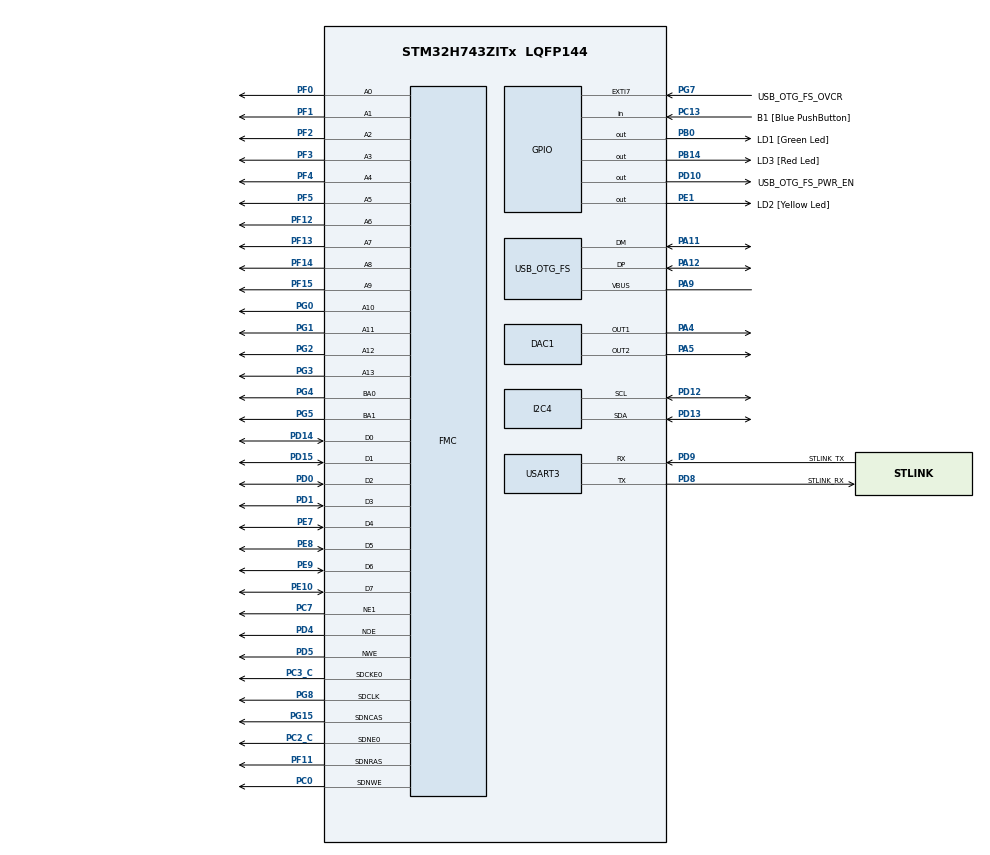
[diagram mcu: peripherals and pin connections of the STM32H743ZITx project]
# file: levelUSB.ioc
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CORTEX_M7.AccessPermission-Cortex_Memory_Protection_Unit_Region0_Settings=MPU_REGION_NO_ACCESS
CORTEX_M7.AccessPermission-Cortex_Memory_Protection_Unit_Region1_Settings=MPU_REGION_FULL_ACCESS
CORTEX_M7.BaseAddress-Cortex_Memory_Protection_Unit_Region0_Settings=0x00
CORTEX_M7.BaseAddress-Cortex_Memory_Protection_Unit_Region1_Settings=0x70000000
CORTEX_M7.CPU_DCache=Enabled
CORTEX_M7.CPU_ICache=Enabled
CORTEX_M7.DisableExec-Cortex_Memory_Protection_Unit_Region0_Settings=MPU_INSTRUCTION_ACCESS_DISABLE
CORTEX_M7.Enable-Cortex_Memory_Protection_Unit_Region0_Settings=MPU_REGION_ENABLE
CORTEX_M7.Enable-Cortex_Memory_Protection_Unit_Region1_Settings=MPU_REGION_ENABLE
CORTEX_M7.IsCacheable-Cortex_Memory_Protection_Unit_Region0_Settings=MPU_ACCESS_NOT_CACHEABLE
CORTEX_M7.IsCacheable-Cortex_Memory_Protection_Unit_Region1_Settings=MPU_ACCESS_CACHEABLE
CORTEX_M7.IsShareable-Cortex_Memory_Protection_Unit_Region0_Settings=MPU_ACCESS_SHAREABLE
CORTEX_M7.MPU_Control=MPU_PRIVILEGED_DEFAULT
CORTEX_M7.Size-Cortex_Memory_Protection_Unit_Region0_Settings=MPU_REGION_SIZE_4GB
CORTEX_M7.Size-Cortex_Memory_Protection_Unit_Region1_Settings=MPU_REGION_SIZE_256MB
CORTEX_M7.SubRegionDisable-Cortex_Memory_Protection_Unit_Region0_Settings=0x87
DAC1.DAC_Channel-DAC_OUT1=DAC_CHANNEL_1
DAC1.DAC_Channel-DAC_OUT2=DAC_CHANNEL_2
FATFS._FS_EXFAT=1
FATFS._FS_RPATH=1
FATFS._MAX_SS=512
FATFS._USE_LFN=3
FATFS._USE_MUTEX=1
FMC.CASLatency1=FMC_SDRAM_CAS_LATENCY_2
FMC.ExitSelfRefreshDelay1=9
FMC.RCDDelay1=2
FMC.RPDelay1=2
FMC.RPDelay2=2
FMC.ReadBurst1=FMC_SDRAM_RBURST_ENABLE
FMC.ReadBurst2=FMC_SDRAM_RBURST_ENABLE
FMC.RowCycleDelay1=8
FMC.RowCycleDelay2=8
FMC.SelfRefreshTime1=4
FMC.WriteOperation1=FMC_WRITE_OPERATION_ENABLE
FMC.WriteRecoveryTime1=4
FREERTOS.Tasks01=startupTask,24,1024,StartDefaultTask,Default,NULL,Dynamic,NULL,NULL
FREERTOS.configMINIMAL_STACK_SIZE=128
FREERTOS.configTOTAL_HEAP_SIZE=35360
FREERTOS.configUSE_NEWLIB_REENTRANT=0
FREERTOS.copyHeapFile=1
I2C4.Timing=0x109093DC
Mcu.Family=STM32H7
Mcu.Name=STM32H743ZITx
Mcu.Package=LQFP144
Mcu.UserConstants=SDRAM_MODEREG_BURST_LENGTH_1,(0x00);SDRAM_MODEREG_BURST_TYPE_SEQUENTIAL,(0x00 << 3);SDRAM_MODEREG_CAS_LATENCY_2,(0x2 << 4);SDRAM_MODEREG_CAS_LATENCY_3,(0x3 << 4);SDRAM_MODEREG_WRITE_BURST_NORMAL,(0x0 << 9);SDRAM_MODEREG_OCD_NORMAL,(0x0 << 10);SDRAM_TIMEOUT,1
Mdma.MDMA_Channel0.Request0=SW
Mdma.MDMA_Channel0.RequestsNb=1
Mdma.MDMA_Channel0.SW.0.BlockCount=0
Mdma.MDMA_Channel0.SW.0.BlockDataLength=0
Mdma.MDMA_Channel0.SW.0.BufferTransferLength=1
Mdma.MDMA_Channel0.SW.0.CircularMode=MDMA_LINEAR_LIST
Mdma.MDMA_Channel0.SW.0.DataAlignment=MDMA_DATAALIGN_PACKENABLE
Mdma.MDMA_Channel0.SW.0.DestBlockAddressOffset=0
Mdma.MDMA_Channel0.SW.0.DestBurst=MDMA_DEST_BURST_SINGLE
Mdma.MDMA_Channel0.SW.0.DestDataSize=MDMA_DEST_DATASIZE_BYTE
Mdma.MDMA_Channel0.SW.0.DestinationInc=MDMA_DEST_INC_BYTE
Mdma.MDMA_Channel0.SW.0.DstAddress=0
Mdma.MDMA_Channel0.SW.0.Endianness=MDMA_LITTLE_ENDIANNESS_PRESERVE
Mdma.MDMA_Channel0.SW.0.Instance=MDMA_Channel0
Mdma.MDMA_Channel0.SW.0.MaskAddress=0
Mdma.MDMA_Channel0.SW.0.MaskData=0
Mdma.MDMA_Channel0.SW.0.Priority=MDMA_PRIORITY_LOW
Mdma.MDMA_Channel0.SW.0.Rank=First
Mdma.MDMA_Channel0.SW.0.SourceBlockAddressOffset=0
Mdma.MDMA_Channel0.SW.0.SourceBurst=MDMA_SOURCE_BURST_SINGLE
Mdma.MDMA_Channel0.SW.0.SourceDataSize=MDMA_SRC_DATASIZE_BYTE
Mdma.MDMA_Channel0.SW.0.SourceInc=MDMA_SRC_INC_BYTE
Mdma.MDMA_Channel0.SW.0.SrcAddress=0
Mdma.MDMA_Channel0.SW.0.TransferTriggerMode=MDMA_BUFFER_TRANSFER
Mdma.MDMA_Channel1.Request0=SW
Mdma.MDMA_Channel1.RequestsNb=1
Mdma.MDMA_Channel1.SW.0.BlockCount=0
Mdma.MDMA_Channel1.SW.0.BlockDataLength=0
Mdma.MDMA_Channel1.SW.0.BufferTransferLength=1
Mdma.MDMA_Channel1.SW.0.CircularMode=MDMA_LINEAR_LIST
Mdma.MDMA_Channel1.SW.0.DataAlignment=MDMA_DATAALIGN_PACKENABLE
Mdma.MDMA_Channel1.SW.0.DestBlockAddressOffset=0
Mdma.MDMA_Channel1.SW.0.DestBurst=MDMA_DEST_BURST_SINGLE
Mdma.MDMA_Channel1.SW.0.DestDataSize=MDMA_DEST_DATASIZE_BYTE
Mdma.MDMA_Channel1.SW.0.DestinationInc=MDMA_DEST_INC_BYTE
Mdma.MDMA_Channel1.SW.0.DstAddress=0
Mdma.MDMA_Channel1.SW.0.Endianness=MDMA_LITTLE_ENDIANNESS_PRESERVE
Mdma.MDMA_Channel1.SW.0.Instance=MDMA_Channel1
Mdma.MDMA_Channel1.SW.0.MaskAddress=0
Mdma.MDMA_Channel1.SW.0.MaskData=0
Mdma.MDMA_Channel1.SW.0.Priority=MDMA_PRIORITY_LOW
Mdma.MDMA_Channel1.SW.0.Rank=First
Mdma.MDMA_Channel1.SW.0.SourceBlockAddressOffset=0
Mdma.MDMA_Channel1.SW.0.SourceBurst=MDMA_SOURCE_BURST_SINGLE
Mdma.MDMA_Channel1.SW.0.SourceDataSize=MDMA_SRC_DATASIZE_BYTE
Mdma.MDMA_Channel1.SW.0.SourceInc=MDMA_SRC_INC_BYTE
Mdma.MDMA_Channel1.SW.0.SrcAddress=0
Mdma.MDMA_Channel1.SW.0.TransferTriggerMode=MDMA_BUFFER_TRANSFER
Mdma.RequestSet0=MDMA_Channel0
Mdma.RequestSet1=MDMA_Channel1
Mdma.RequestSetsNb=2
NVIC.FMC_IRQn=true\:5\:0\:false\:false\:true\:true\:true\:true
NVIC.MDMA_IRQn=true\:5\:0\:false\:false\:true\:true\:false\:true
NVIC.OTG_FS_IRQn=true\:5\:0\:false\:false\:true\:true\:true\:true
NVIC.PriorityGroup=NVIC_PRIORITYGROUP_4
NVIC.TIM6_DAC_IRQn=true\:5\:0\:false\:false\:true\:false\:true\:true
NVIC.TIM7_IRQn=true\:5\:0\:false\:false\:true\:true\:true\:true
NVIC.TimeBase=TIM6_DAC_IRQn
NVIC.TimeBaseIP=TIM6
PA1.Signal=ETH_REF_CLK
PA11.Mode=Host_Only
PA11.Signal=USB_OTG_FS_DM
PA12.Mode=Host_Only
PA12.Signal=USB_OTG_FS_DP
PA13\ (JTMS/SWDIO).Mode=Serial_Wire
PA13\ (JTMS/SWDIO).Signal=DEBUG_JTMS-SWDIO
PA14\ (JTCK/SWCLK).Mode=Serial_Wire
PA14\ (JTCK/SWCLK).Signal=DEBUG_JTCK-SWCLK
PA2.Signal=ETH_MDIO
PA4.Signal=COMP_DAC11_group
PA5.Signal=COMP_DAC12_group
PA7.Signal=ETH_CRS_DV
PA8.Signal=USB_OTG_FS_SOF
PA9.Mode=Activate_VBUS
PA9.Signal=USB_OTG_FS_VBUS
PB0.GPIO_Label=LD1 [Green Led]
PB0.Signal=GPIO_Output
PB13.Signal=ETH_TXD1
PB14.GPIO_Label=LD3 [Red Led]
PB14.Signal=GPIO_Output
PB8.Signal=I2C1_SCL
PB9.Signal=I2C1_SDA
PC0.Signal=FMC_SDNWE
PC1.Signal=ETH_MDC
PC13.GPIO_Label=B1 [Blue PushButton]
PC13.Signal=GPIO_Input
PC14-OSC32_IN\ (OSC32_IN).Signal=RCC_OSC32_IN
PC15-OSC32_OUT\ (OSC32_OUT).Signal=RCC_OSC32_OUT
PC2_C.Mode=SdramChipSelect1_1
PC2_C.Signal=FMC_SDNE0
PC3_C.Mode=SdramChipSelect1_1
PC3_C.Signal=FMC_SDCKE0
PC4.Signal=ETH_RXD0
PC5.Signal=ETH_RXD1
PC7.Mode=NorPsramChipSelect1_1
PC7.Signal=FMC_NE1
PD0.Signal=FMC_D2_DA2
PD1.Signal=FMC_D3_DA3
PD10.GPIO_Label=USB_OTG_FS_PWR_EN
PD10.Signal=GPIO_Output
PD12.Mode=I2C
PD12.Signal=I2C4_SCL
PD13.Mode=I2C
PD13.Signal=I2C4_SDA
PD14.Signal=FMC_D0_DA0
PD15.Signal=FMC_D1_DA1
PD4.Signal=FMC_NOE
PD5.Signal=FMC_NWE
PD8.GPIO_Label=STLINK_RX
PD8.Mode=Asynchronous
PD8.Signal=USART3_TX
PD9.GPIO_Label=STLINK_TX
PD9.Mode=Asynchronous
PD9.Signal=USART3_RX
PE1.GPIO_Label=LD2 [Yellow Led]
PE1.Signal=GPIO_Output
PE10.Signal=FMC_D7_DA7
PE7.Signal=FMC_D4_DA4
PE8.Signal=FMC_D5_DA5
PE9.Signal=FMC_D6_DA6
PF0.Signal=FMC_A0
PF1.Signal=FMC_A1
PF11.Signal=FMC_SDNRAS
PF12.Signal=FMC_A6
PF13.Signal=FMC_A7
PF14.Signal=FMC_A8
PF15.Signal=FMC_A9
PF2.Signal=FMC_A2
PF3.Signal=FMC_A3
PF4.Signal=FMC_A4
PF5.Signal=FMC_A5
PG0.Signal=FMC_A10
PG1.Signal=FMC_A11
PG11.Signal=ETH_TX_EN
PG13.Signal=ETH_TXD0
PG15.Signal=FMC_SDNCAS
PG2.Signal=FMC_A12
PG3.Signal=FMC_A13
PG4.Signal=FMC_A14_BA0
PG5.Signal=FMC_A15_BA1
PG7.GPIO_Label=USB_OTG_FS_OVCR
PG7.Signal=GPXTI7
PG8.Signal=FMC_SDCLK
PH0-OSC_IN\ (PH0).Mode=HSE-External-Oscillator
PH0-OSC_IN\ (PH0).Signal=RCC_OSC_IN
PH1-OSC_OUT\ (PH1).Mode=HSE-External-Oscillator
PH1-OSC_OUT\ (PH1).Signal=RCC_OSC_OUT
ProjectManager.HeapSize=0x200
ProjectManager.StackSize=0x400
ProjectManager.TargetToolchain=STM32CubeIDE
RCC.ADCFreq_Value=16125000
RCC.APB1Freq_Value=120000000
RCC.APB2Freq_Value=120000000
RCC.APB3Freq_Value=120000000
RCC.APB4Freq_Value=120000000
RCC.CortexFreq_Value=240000000
RCC.DIVM1=2
RCC.DIVM3=2
RCC.DIVN1=120
RCC.DIVN3=75
RCC.DIVQ1=8
RCC.DIVR3=4
RCC.FLatency-AdvancedSettings=FLASH_LATENCY_0
RCC.HCLKFreq_Value=120000000
RCC.HPRE=RCC_HCLK_DIV2
RCC.HSE_VALUE=8000000
RCC.I2C123CLockSelection=RCC_I2C123CLKSOURCE_PLL3
RCC.I2C4CLockSelection=RCC_I2C4CLKSOURCE_PLL3
RCC.PLL1_VCI_Range-AdvancedSettings=RCC_PLL1VCIRANGE_0
RCC.PLL2_VCI_Range-AdvancedSettings=RCC_PLL2VCIRANGE_0
RCC.PLLFRACN=0
RCC.PWR_Regulator_Voltage_Scale=PWR_REGULATOR_VOLTAGE_SCALE2
RCC.SYSCLKFreq_VALUE=240000000
RCC.SYSCLKSource=RCC_SYSCLKSOURCE_PLLCLK
RCC.USART234578CLockSelection=RCC_USART234578CLKSOURCE_HSI
RCC.USBFreq_Value=60000000
SH.COMP_DAC11_group.0=DAC1_OUT1,DAC_OUT1
SH.COMP_DAC12_group.0=DAC1_OUT2,DAC_OUT2
SH.FMC_A0.0=FMC_A0,12b-sda1
SH.FMC_A0.1=FMC_A0,15b-a1
SH.FMC_A1.0=FMC_A1,12b-sda1
SH.FMC_A1.1=FMC_A1,15b-a1
SH.FMC_A10.0=FMC_A10,12b-sda1
SH.FMC_A10.1=FMC_A10,15b-a1
SH.FMC_A11.0=FMC_A11,12b-sda1
SH.FMC_A11.1=FMC_A11,15b-a1
SH.FMC_A12.0=FMC_A12,15b-a1
SH.FMC_A13.0=FMC_A13,15b-a1
SH.FMC_A14_BA0.0=FMC_BA0,FourSdramBanks1
SH.FMC_A14_BA0.1=FMC_A14,15b-a1
SH.FMC_A15_BA1.0=FMC_BA1,FourSdramBanks1
SH.FMC_A2.0=FMC_A2,12b-sda1
SH.FMC_A2.1=FMC_A2,15b-a1
SH.FMC_A3.0=FMC_A3,12b-sda1
SH.FMC_A3.1=FMC_A3,15b-a1
SH.FMC_A4.0=FMC_A4,12b-sda1
SH.FMC_A4.1=FMC_A4,15b-a1
SH.FMC_A5.0=FMC_A5,12b-sda1
SH.FMC_A5.1=FMC_A5,15b-a1
SH.FMC_A6.0=FMC_A6,12b-sda1
SH.FMC_A6.1=FMC_A6,15b-a1
SH.FMC_A7.0=FMC_A7,12b-sda1
SH.FMC_A7.1=FMC_A7,15b-a1
SH.FMC_A8.0=FMC_A8,12b-sda1
SH.FMC_A8.1=FMC_A8,15b-a1
SH.FMC_A9.0=FMC_A9,12b-sda1
SH.FMC_A9.1=FMC_A9,15b-a1
SH.FMC_D0_DA0.0=FMC_D0,sd-8b-d1
SH.FMC_D0_DA0.1=FMC_D0,8b-d1
SH.FMC_D1_DA1.0=FMC_D1,sd-8b-d1
SH.FMC_D1_DA1.1=FMC_D1,8b-d1
SH.FMC_D2_DA2.0=FMC_D2,sd-8b-d1
SH.FMC_D2_DA2.1=FMC_D2,8b-d1
SH.FMC_D3_DA3.0=FMC_D3,sd-8b-d1
SH.FMC_D3_DA3.1=FMC_D3,8b-d1
SH.FMC_D4_DA4.0=FMC_D4,sd-8b-d1
SH.FMC_D4_DA4.1=FMC_D4,8b-d1
SH.FMC_D5_DA5.0=FMC_D5,sd-8b-d1
SH.FMC_D5_DA5.1=FMC_D5,8b-d1
SH.FMC_D6_DA6.0=FMC_D6,sd-8b-d1
SH.FMC_D6_DA6.1=FMC_D6,8b-d1
SH.FMC_D7_DA7.0=FMC_D7,sd-8b-d1
SH.FMC_D7_DA7.1=FMC_D7,8b-d1
SH.FMC_NOE.0=FMC_NOE,Sram1
SH.FMC_NWE.0=FMC_NWE,Sram1
SH.FMC_SDCLK.0=FMC_SDCLK,12b-sda1
SH.FMC_SDNCAS.0=FMC_SDNCAS,12b-sda1
SH.FMC_SDNRAS.0=FMC_SDNRAS,12b-sda1
SH.FMC_SDNWE.0=FMC_SDNWE,12b-sda1
TIM7.AutoReloadPreload=TIM_AUTORELOAD_PRELOAD_ENABLE
TIM7.Period=2499
TIM7.TIM_MasterOutputTrigger=TIM_TRGO_UPDATE
USART3.VirtualMode-Asynchronous=VM_ASYNC
USB_HOST.BSP.number=1
USB_HOST.USBH_HandleTypeDef-MSC_FS=hUsbHostFS
USB_HOST.USBH_PROCESS_STACK_SIZE-MSC_FS=512
USB_HOST.VirtualModeFS=Msc
USB_HOST0.BSP.STBoard=false
USB_HOST0.BSP.api=Unknown
USB_HOST0.BSP.i2caddr=0
USB_HOST0.BSP.instance=PD10
USB_HOST0.BSP.ip=GPIO
USB_HOST0.BSP.mode=Output
USB_HOST0.BSP.name=Drive_VBUS_FS
USB_HOST0.BSP.solution=PD10
USB_OTG_FS.VirtualMode=Host_Only
USB_OTG_FS.dma_enable=ENABLE
USB_OTG_FS.phy_itface=HCD_PHY_EMBEDDED
VP_FATFS_VS_USB.Mode=USB
VP_FREERTOS_VS_CMSIS_V2.Mode=CMSIS_V2
VP_SYS_VS_tim6.Mode=TIM6
VP_TIM7_VS_ClockSourceINT.Mode=Enable_Timer
VP_USB_HOST_VS_USB_HOST_MSC_FS.Mode=MSC_FS
board=NUCLEO-H743ZI2

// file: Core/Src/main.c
/* USER CODE BEGIN Header */
/**
  ******************************************************************************
  * @file           : main.c
  * @brief          : Main program body
  ******************************************************************************
  * @attention
  *
  * <h2><center>&copy; Copyright (c) 2021 STMicroelectronics.
  * All rights reserved.</center></h2>
  *
  * This software component is licensed by ST under BSD 3-Clause license,
  * the "License"; You may not use this file except in compliance with the
  * License. You may obtain a copy of the License at:
  *                        opensource.org/licenses/BSD-3-Clause
  *
  ******************************************************************************
  */
/* USER CODE END Header */
#include "main.h"
#include "cmsis_os.h"
#include "dac.h"
#include "fatfs.h"
#include "i2c.h"
#include "mdma.h"
#include "tim.h"
#include "usart.h"
#include "usb_host.h"
#include "gpio.h"
#include "fmc.h"

void SystemClock_Config(void);
static void MPU_Config(void);
void MX_FREERTOS_Init(void);

/* USER CODE BEGIN 0 */
int _write(int file, char *ptr, int len)
{
	int DataIdx;

	for (DataIdx = 0; DataIdx < len; DataIdx++)
	{
		ITM_SendChar(*ptr++);
	}
	return len;
}
/* USER CODE END 0 */

int main(void)
{

  /* MPU Configuration--------------------------------------------------------*/
  MPU_Config();

  /* Enable I-Cache---------------------------------------------------------*/
  SCB_EnableICache();

  /* Enable D-Cache---------------------------------------------------------*/
  SCB_EnableDCache();

  /* MCU Configuration--------------------------------------------------------*/

  /* Reset of all peripherals, Initializes the Flash interface and the Systick. */
  HAL_Init();

  /* Configure the system clock */
  SystemClock_Config();

  /* Initialize all configured peripherals */
  MX_GPIO_Init();
  MX_USART3_UART_Init();
  MX_FATFS_Init();
  MX_MDMA_Init();
  MX_FMC_Init();
  MX_DAC1_Init();
  MX_TIM7_Init();
  MX_I2C4_Init();

  /* Init scheduler */
  osKernelInitialize();  /* Call init function for freertos objects (in freertos.c) */
  MX_FREERTOS_Init();
  /* Start scheduler */
  osKernelStart();

  /* We should never get here as control is now taken by the scheduler */
  /* Infinite loop */
  while (1)
  {

  }
}

void SystemClock_Config(void)
{
  RCC_OscInitTypeDef RCC_OscInitStruct = {0};
  RCC_ClkInitTypeDef RCC_ClkInitStruct = {0};

  /** Supply configuration update enable
  */
  HAL_PWREx_ConfigSupply(PWR_LDO_SUPPLY);
  /** Configure the main internal regulator output voltage
  */
  __HAL_PWR_VOLTAGESCALING_CONFIG(PWR_REGULATOR_VOLTAGE_SCALE2);

  while(!__HAL_PWR_GET_FLAG(PWR_FLAG_VOSRDY)) {}
  /** Macro to configure the PLL clock source
  */
  __HAL_RCC_PLL_PLLSOURCE_CONFIG(RCC_PLLSOURCE_HSE);
  /** Initializes the RCC Oscillators according to the specified parameters
  * in the RCC_OscInitTypeDef structure.
  */
  RCC_OscInitStruct.OscillatorType = RCC_OSCILLATORTYPE_HSI|RCC_OSCILLATORTYPE_HSE;
  RCC_OscInitStruct.HSEState = RCC_HSE_ON;
  RCC_OscInitStruct.HSIState = RCC_HSI_DIV1;
  RCC_OscInitStruct.HSICalibrationValue = RCC_HSICALIBRATION_DEFAULT;
  RCC_OscInitStruct.PLL.PLLState = RCC_PLL_ON;
  RCC_OscInitStruct.PLL.PLLSource = RCC_PLLSOURCE_HSE;
  RCC_OscInitStruct.PLL.PLLM = 2;
  RCC_OscInitStruct.PLL.PLLN = 120;
  RCC_OscInitStruct.PLL.PLLP = 2;
  RCC_OscInitStruct.PLL.PLLQ = 8;
  RCC_OscInitStruct.PLL.PLLR = 2;
  RCC_OscInitStruct.PLL.PLLRGE = RCC_PLL1VCIRANGE_2;
  RCC_OscInitStruct.PLL.PLLVCOSEL = RCC_PLL1VCOWIDE;
  RCC_OscInitStruct.PLL.PLLFRACN = 0;
  if (HAL_RCC_OscConfig(&RCC_OscInitStruct) != HAL_OK)
  {
    Error_Handler();
  }
  /** Initializes the CPU, AHB and APB buses clocks
  */
  RCC_ClkInitStruct.ClockType = RCC_CLOCKTYPE_HCLK|RCC_CLOCKTYPE_SYSCLK
                              |RCC_CLOCKTYPE_PCLK1|RCC_CLOCKTYPE_PCLK2
                              |RCC_CLOCKTYPE_D3PCLK1|RCC_CLOCKTYPE_D1PCLK1;
  RCC_ClkInitStruct.SYSCLKSource = RCC_SYSCLKSOURCE_PLLCLK;
  RCC_ClkInitStruct.SYSCLKDivider = RCC_SYSCLK_DIV1;
  RCC_ClkInitStruct.AHBCLKDivider = RCC_HCLK_DIV2;
  RCC_ClkInitStruct.APB3CLKDivider = RCC_APB3_DIV1;
  RCC_ClkInitStruct.APB1CLKDivider = RCC_APB1_DIV1;
  RCC_ClkInitStruct.APB2CLKDivider = RCC_APB2_DIV1;
  RCC_ClkInitStruct.APB4CLKDivider = RCC_APB4_DIV1;

  if (HAL_RCC_ClockConfig(&RCC_ClkInitStruct, FLASH_LATENCY_2) != HAL_OK)
  {
    Error_Handler();
  }
}

/* MPU Configuration */

void MPU_Config(void)
{
  MPU_Region_InitTypeDef MPU_InitStruct = {0};

  /* Disables the MPU */
  HAL_MPU_Disable();
  /** Initializes and configures the Region and the memory to be protected
  */
  MPU_InitStruct.Enable = MPU_REGION_ENABLE;
  MPU_InitStruct.Number = MPU_REGION_NUMBER0;
  MPU_InitStruct.BaseAddress = 0x00;
  MPU_InitStruct.Size = MPU_REGION_SIZE_4GB;
  MPU_InitStruct.SubRegionDisable = 0x87;
  MPU_InitStruct.TypeExtField = MPU_TEX_LEVEL0;
  MPU_InitStruct.AccessPermission = MPU_REGION_NO_ACCESS;
  MPU_InitStruct.DisableExec = MPU_INSTRUCTION_ACCESS_DISABLE;
  MPU_InitStruct.IsShareable = MPU_ACCESS_SHAREABLE;
  MPU_InitStruct.IsCacheable = MPU_ACCESS_NOT_CACHEABLE;
  MPU_InitStruct.IsBufferable = MPU_ACCESS_NOT_BUFFERABLE;

  HAL_MPU_ConfigRegion(&MPU_InitStruct);
  /** Initializes and configures the Region and the memory to be protected
  */
  MPU_InitStruct.Number = MPU_REGION_NUMBER1;
  MPU_InitStruct.BaseAddress = 0x70000000;
  MPU_InitStruct.Size = MPU_REGION_SIZE_256MB;
  MPU_InitStruct.SubRegionDisable = 0x0;
  MPU_InitStruct.AccessPermission = MPU_REGION_FULL_ACCESS;
  MPU_InitStruct.DisableExec = MPU_INSTRUCTION_ACCESS_ENABLE;
  MPU_InitStruct.IsShareable = MPU_ACCESS_NOT_SHAREABLE;
  MPU_InitStruct.IsCacheable = MPU_ACCESS_CACHEABLE;

  HAL_MPU_ConfigRegion(&MPU_InitStruct);
  /* Enables the MPU */
  HAL_MPU_Enable(MPU_PRIVILEGED_DEFAULT);

}

void HAL_TIM_PeriodElapsedCallback(TIM_HandleTypeDef *htim)
{
  if (htim->Instance == TIM6) {
    HAL_IncTick();
  }
}

void Error_Handler(void)
{
  __disable_irq();
  while (1)
  {
  }
}

/************************ (C) COPYRIGHT STMicroelectronics *****END OF FILE****/

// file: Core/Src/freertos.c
/* USER CODE BEGIN Header */
/**
  ******************************************************************************
  * File Name          : freertos.c
  * Description        : Code for freertos applications
  ******************************************************************************
  * @attention
  *
  * <h2><center>&copy; Copyright (c) 2021 STMicroelectronics.
  * All rights reserved.</center></h2>
  *
  * This software component is licensed by ST under Ultimate Liberty license
  * SLA0044, the "License"; You may not use this file except in compliance with
  * the License. You may obtain a copy of the License at:
  *                             www.st.com/SLA0044
  *
  ******************************************************************************
  */
/* USER CODE END Header */

#include "FreeRTOS.h"
#include "task.h"
#include "main.h"
#include "cmsis_os.h"

/* USER CODE BEGIN Includes */
#include "stdio.h"
#include "fatfs.h"
#include "usb_host.h"
#include "sparkboxStartup.hpp"
extern volatile ApplicationTypeDef Appli_state;
/* USER CODE END Includes */

/* Definitions for startupTask */
osThreadId_t startupTaskHandle;
const osThreadAttr_t startupTask_attributes = {
  .name = "startupTask",
  .stack_size = 1024 * 4,
  .priority = (osPriority_t) osPriorityNormal,
};

/* USER CODE BEGIN FunctionPrototypes */
void testFatfs();
/* USER CODE END FunctionPrototypes */

void StartDefaultTask(void *argument);

extern void MX_USB_HOST_Init(void);
void MX_FREERTOS_Init(void); /* (MISRA C 2004 rule 8.1) */

void MX_FREERTOS_Init(void) {

  /* Create the thread(s) */
  /* creation of startupTask */
  startupTaskHandle = osThreadNew(StartDefaultTask, NULL, &startupTask_attributes);

}

void StartDefaultTask(void *argument)
{
  /* init code for USB_HOST */
  MX_USB_HOST_Init();
  /* USER CODE BEGIN StartDefaultTask */
  levelStartupTask(argument);
  /* Infinite loop */
  for(;;)
  {

  }
  /* USER CODE END StartDefaultTask */
}

/************************ (C) COPYRIGHT STMicroelectronics *****END OF FILE****/
